VERSION ""

NS_ :

BS_:

BU_: MC Charger ELCON Controller Peripheral

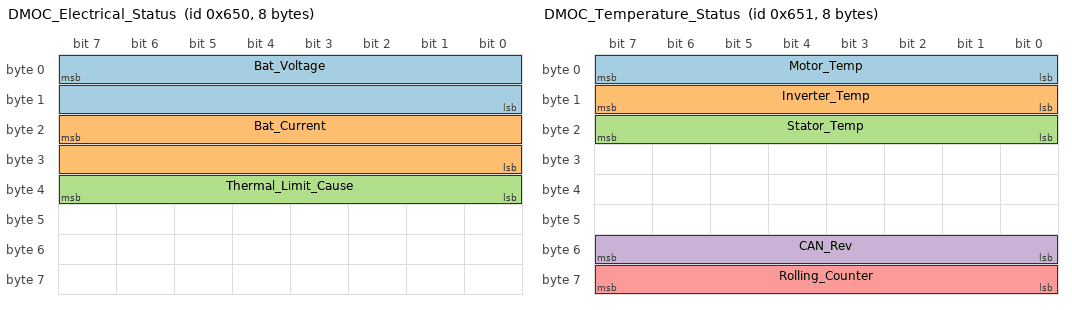
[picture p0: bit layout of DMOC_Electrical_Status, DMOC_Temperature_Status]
BO_ 1616 DMOC_Electrical_Status: 8 MC
 SG_ Bat_Voltage : 7|16@0+ (0.1,0) [0|1000] "V" Controller
 SG_ Bat_Current : 23|16@0- (0.1,-500) [-500|500] "A" Controller
 SG_ Thermal_Limit_Cause : 39|8@0+ (1,0) [0|240] "" Controller

BO_ 1617 DMOC_Temperature_Status: 8 MC
 SG_ Motor_Temp : 7|8@0+ (1,-40) [-40|200] "degC" Controller
 SG_ Inverter_Temp : 15|8@0+ (1,-40) [-40|200] "degC" Controller
 SG_ Stator_Temp : 23|8@0+ (1,-40) [-40|200] "degC" Controller
 SG_ CAN_Rev : 55|8@0+ (1,0) [0|255] "" Controller
 SG_ Rolling_Counter : 63|8@0+ (1,0) [0|255] "" Controller

BO_ 570 DMOC_Torque_Actual: 8 MC
 SG_ Torque_Actual : 7|16@0- (0.1,-3000) [-3000|3000] "Nm" Controller

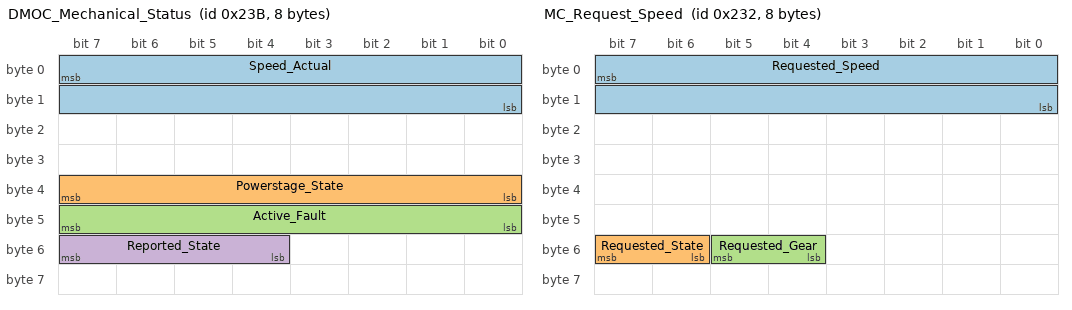
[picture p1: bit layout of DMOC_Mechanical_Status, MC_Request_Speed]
BO_ 571 DMOC_Mechanical_Status: 8 MC
 SG_ Speed_Actual : 7|16@0- (1,-20000) [-20000|20000] "rpm" Controller
 SG_ Powerstage_State : 39|8@0+ (1,0) [0|7] "" Controller
 SG_ Active_Fault : 47|8@0+ (1,0) [0|255] "" Controller
 SG_ Reported_State : 55|4@0+ (1,0) [0|7] "" Controller

BO_ 562 MC_Request_Speed: 8 MC
 SG_ Requested_Speed : 7|16@0+ (1,0) [0|0] "" MC
 SG_ Requested_State : 55|2@0+ (1,0) [0|3] "" MC
 SG_ Requested_Gear : 53|2@0+ (1,0) [0|3] "" MC

BO_ 563 MC_Torque_Request: 8 MC
 SG_ Torque_Requested : 7|16@0+ (1,0) [0|0] "" MC
 SG_ Torque_Limit : 23|16@0+ (1,0) [0|0] "" MC

BO_ 564 MC_Limits: 8 MC
 SG_ Regen_Limit : 7|16@0+ (1,0) [0|0] "" MC
 SG_ Accel_Limit : 23|16@0+ (1,0) [0|0] "" MC

BO_ 565 MC_0x235: 8 MC

BO_ 566 MC_0x236: 8 MC

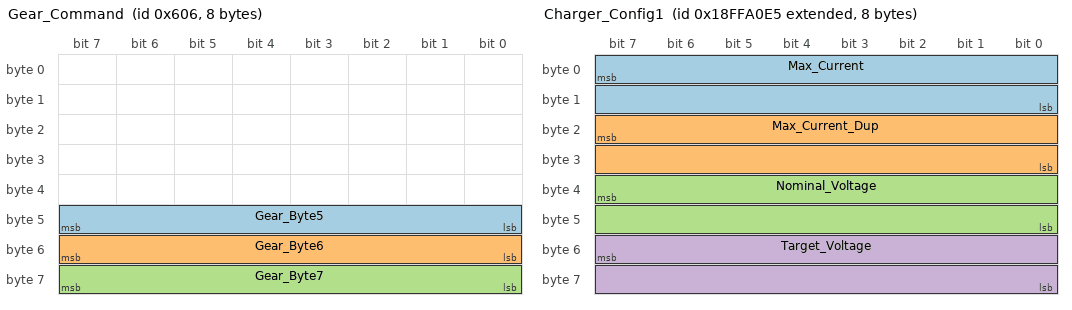
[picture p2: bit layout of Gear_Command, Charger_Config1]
BO_ 1542 Gear_Command: 8 Controller
 SG_ Gear_Byte5 : 47|8@0+ (1,0) [0|255] "" MC
 SG_ Gear_Byte6 : 55|8@0+ (1,0) [0|255] "" MC
 SG_ Gear_Byte7 : 63|8@0+ (1,0) [0|255] "" MC

BO_ 1543 PreCharge_Status: 8 MC
 SG_ PreCharge_Status_Raw : 15|8@0+ (1,0) [0|255] "" Controller

BO_ 1545 Gear_Confirmation: 8 MC

BO_ 2566889701 Charger_Config1: 8 Charger
 SG_ Max_Current : 7|16@0+ (0.1,0) [0|0] "A" Controller
 SG_ Max_Current_Dup : 23|16@0+ (0.1,0) [0|0] "A" Controller
 SG_ Nominal_Voltage : 39|16@0+ (0.1,0) [0|0] "V" Controller
 SG_ Target_Voltage : 55|16@0+ (0.1,0) [0|0] "V" Controller

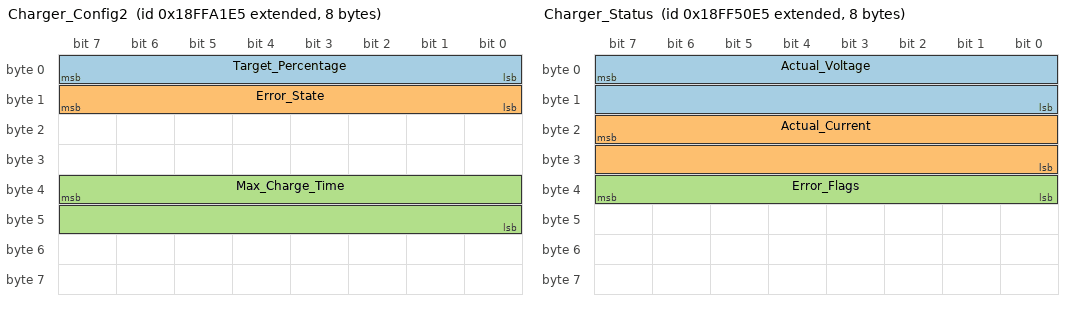
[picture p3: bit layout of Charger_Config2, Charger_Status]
BO_ 2566889957 Charger_Config2: 8 Charger
 SG_ Target_Percentage : 7|8@0+ (1,0) [0|100] "%" Controller
 SG_ Error_State : 15|8@0+ (1,0) [0|255] "" Controller
 SG_ Max_Charge_Time : 39|16@0+ (1,0) [0|65535] "s" Controller

BO_ 2566869221 Charger_Status: 8 ELCON
 SG_ Actual_Voltage : 7|16@0+ (0.1,0) [0|0] "V" Controller
 SG_ Actual_Current : 23|16@0+ (0.1,0) [0|0] "A" Controller
 SG_ Error_Flags : 39|8@0+ (1,0) [0|255] "" Controller

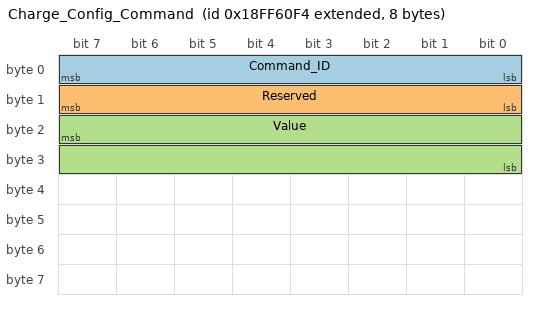
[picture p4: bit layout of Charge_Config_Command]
BO_ 2566873332 Charge_Config_Command: 8 Controller
 SG_ Command_ID : 7|8@0+ (1,0) [0|3] "" Charger
 SG_ Reserved : 15|8@0+ (1,0) [0|0] "" Charger
 SG_ Value : 23|16@0+ (1,0) [0|65535] "" Charger

CM_ BU_ MC "Azure Dynamics DMOC445/DMOC645 motor controller";
CM_ BU_ Charger "pao_charger - Arduino-based CAN charge manager";
CM_ BU_ ELCON "ELCON hardware charger, J1939 broadcast";
CM_ BU_ Controller "pao_console_dial controller MCU (Feather M0)";
CM_ BU_ Peripheral "pao_console_dial peripheral MCU (ESP32-S3, display)";

CM_ BO_ 1616 "0x650 - DMOC Electrical Status Message (EEXCANElecStatus1ID). Ref: MAN-080002-001 Table 13. ISR2BatVoltageWF = filtered DC bus voltage. ISR2EstBatCurrent = estimated battery current. ISR2ThermCurrentLimitCause = thermal derating reason. TX rate configurable via EEXCANElecStatus1CycleSec.";
CM_ BO_ 1617 "0x651 - DMOC Temperature Status Message (EEXCANTempStatusID). Ref: MAN-080002-001 Table 13. Motor_Temp = ISR2MotorLimit (PTC-based, only 3 discrete values: 20C=OK, 120C=derated, 200C=limited). Inverter_Temp = ISR2HeatsinkTemp. Bytes 2-5 reserved per spec; Stator_Temp at byte 2 may be firmware-specific. CAN_Rev = FRC_CAN_REV interface level. Rolling_Counter increments each message.";
CM_ BO_ 570  "0x23A - DMOC torque feedback. ISR2RealTorque. Equivalent to Mechanical Status bytes 0-1 at configured ID. physical_Nm = raw * 0.1 - 3000. Example: 0x7530 (30000) = 0 Nm.";
CM_ BO_ 571  "0x23B - DMOC mechanical/speed status. Speed_Actual = ISR2HertzWF (motor electrical frequency in rpm equivalent). physical_rpm = raw - 20000. Powerstage_State and Active_Fault at bytes 4-5 per Mechanical Status spec (MAN-080002-001 Table 13). Reported_State is upper nibble of byte 6 (ISR2StatusCode MSB nibble) as parsed by pao_console_dial firmware.";
CM_ BO_ 562  "0x232 - Speed/state/gear requests monitored from upstream controller. State in bits[7:6] of byte 6; gear in bits[5:4]";
CM_ BO_ 563  "0x233 - Requested torque and torque limit monitored from upstream controller";
CM_ BO_ 564  "0x234 - Regen and acceleration limits monitored from upstream controller";
CM_ BO_ 565  "0x235 - Unimplemented (no signals parsed)";
CM_ BO_ 566  "0x236 - Unimplemented (no signals parsed)";
CM_ BO_ 1542 "0x606 - Gear command to DMOC. NEUTRAL: all 0. DRIVE: byte6=0xFF byte7=0x88. REVERSE: byte6=0x88 byte7=0xFF. PARK: byte5=0xFF bytes6-7=0x00";
CM_ BO_ 1543 "0x607 - Pre-charge contactor ready. byte1: 0x88=ready, 0xFF=not ready";
CM_ BO_ 1545 "0x609 - Gear change confirmation from motor controller (no payload parsed)";
CM_ BO_ 2566889701 "0x18FFA0E5 - pao_charger config broadcast 1. bytes[0:1]=maxCurrent, bytes[2:3]=maxCurrent(dup), bytes[4:5]=nominalVoltage, bytes[6:7]=targetVoltage. All in 0.1 V / 0.1 A";
CM_ BO_ 2566889957 "0x18FFA1E5 - pao_charger config broadcast 2. Target_Percentage is the configured charge LIMIT (e.g. 95), not actual SOC. bytes[2:3] not used. Max_Charge_Time in seconds";
CM_ BO_ 2566869221 "0x18FF50E5 - ELCON hardware charger status. Actual voltage and current from charger output. Error_Flags bitmask at byte 4";
CM_ BO_ 2566873332 "0x18FF60F4 - Charge config command from pao_console_dial to pao_charger. Sent repeatedly until charger confirms via broadcast. Value encoding depends on Command_ID";

CM_ SG_ 1616 Bat_Voltage "ISR2BatVoltageWF - filtered DC bus voltage. physical = raw * 0.1 V";
CM_ SG_ 1616 Bat_Current "ISR2EstBatCurrent - estimated battery current. physical = raw * 0.1 - 500 A. Positive = discharge.";
CM_ SG_ 1616 Thermal_Limit_Cause "ISR2ThermCurrentLimitCause - reason for thermal current derating. 0 = no limit.";
CM_ SG_ 1617 Motor_Temp "ISR2MotorLimit - motor stator PTC temperature. Only 3 valid values: 20C (OK), 120C (derated), 200C (thermally limited). Values 241-255 indicate sensor error.";
CM_ SG_ 1617 Inverter_Temp "ISR2HeatsinkTemp - DMOC heatsink temperature. Values 241-255 indicate sensor error.";
CM_ SG_ 1617 Rolling_Counter "Increments with each transmitted message. Use to verify DMOC is alive.";
CM_ SG_ 570 Torque_Actual "ISR2RealTorque - actual motor torque. physical = raw * 0.1 - 3000 Nm. Zero torque = raw 30000 (0x7530).";
CM_ SG_ 571 Speed_Actual "ISR2HertzWF - motor speed. physical = raw - 20000 rpm. Zero speed = raw 20000 (0x4E20).";
CM_ SG_ 571 Powerstage_State "ISR2PowerStageState - DMOC power stage state (byte 4 per MAN-080002-001 Table 13).";
CM_ SG_ 571 Active_Fault "ISR2PSFaultActive - active fault enum (byte 5 per MAN-080002-001 Table 13). See DMOC445/DMOC645 User Manual for fault codes.";
CM_ SG_ 571 Reported_State "Upper nibble of byte 6 (ISR2StatusCode) as parsed by pao_console_dial. Maps to DMOC powerstage state enum.";
CM_ SG_ 1543 PreCharge_Status_Raw "0x88 = pre-charge ready (HIGH); 0xFF = not ready (LOW)";
CM_ SG_ 2566889957 Target_Percentage "Configured charge limit percent (0-100). NOT current SOC. Estimated SOC = (Actual_Voltage / Target_Voltage) * Target_Percentage";
CM_ SG_ 2566873332 Command_ID "1=set_max_time, 2=set_target_pct, 3=set_target_amps";
CM_ SG_ 2566873332 Value "cmd=1: seconds (uint16). cmd=2: target_pct * 10 (e.g. 950 = 95%). cmd=3: amps in 0.1 A units (e.g. 150 = 15.0 A)";

 0 "Initializing"
 1 "Disabled"
 2 "Standby"
 3 "Enabled"
 4 "PowerDown"
 5 "Fault"
 6 "CriticalFault"
 7 "LOS" ;

 0 "Initializing"
 1 "Disabled"
 2 "Standby"
 3 "Enabled"
 4 "PowerDown"
 5 "Fault"
 6 "CriticalFault"
 7 "LOS" ;

 1 "SetMaxTime"
 2 "SetTargetPct"
 3 "SetTargetAmps" ;
